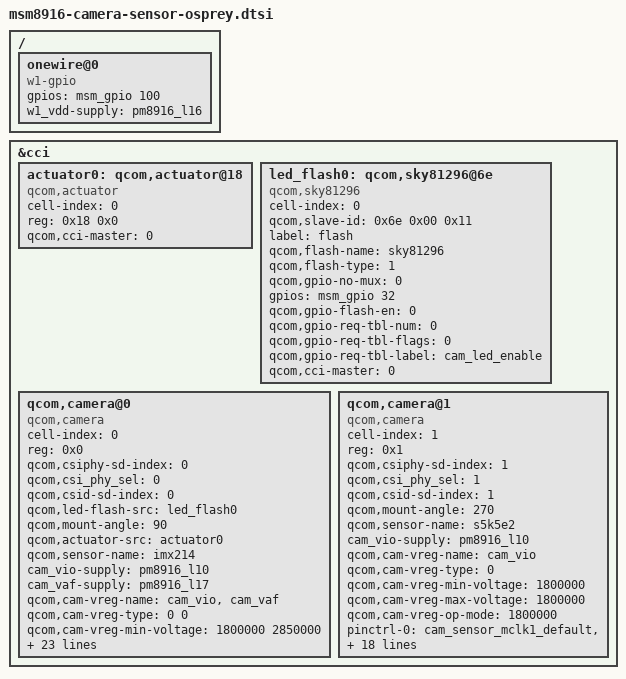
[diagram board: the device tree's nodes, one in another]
/*
 * Copyright (c) 2014, The Linux Foundation. All rights reserved.
 *
 * This program is free software; you can redistribute it and/or modify
 * it under the terms of the GNU General Public License version 2 and
 * only version 2 as published by the Free Software Foundation.
 *
 * This program is distributed in the hope that it will be useful,
 * but WITHOUT ANY WARRANTY; without even the implied warranty of
 * MERCHANTABILITY or FITNESS FOR A PARTICULAR PURPOSE.  See the
 * GNU General Public License for more details.
 */

/ {
	onewire@0 {
		compatible = "w1-gpio";
		gpios = <&msm_gpio 100 0>;
		w1_vdd-supply = <&pm8916_l16>;
	};
};

&cci {
	actuator0: qcom,actuator@18 {
		cell-index = <0>;
		reg = <0x18 0x0>;
		compatible = "qcom,actuator";
		qcom,cci-master = <0>;
	};

	/* skyworks sky81296 flash LED driver*/
	led_flash0: qcom,sky81296@6e {
		cell-index = <0>;
		qcom,slave-id = <0x6e 0x00 0x11>;
		compatible = "qcom,sky81296";
		label = "flash";
		qcom,flash-name = "sky81296";
		qcom,flash-type = <1>;
		qcom,gpio-no-mux = <0>;
		gpios = <&msm_gpio 32 0>;
		qcom,gpio-flash-en = <0>;
		qcom,gpio-req-tbl-num = <0>;
		qcom,gpio-req-tbl-flags = <0>;
		qcom,gpio-req-tbl-label = "cam_led_enable";
		qcom,cci-master = <0>;
	};

	qcom,camera@0 {
		cell-index = <0>;
		compatible = "qcom,camera";
		reg = <0x0>;
		qcom,csiphy-sd-index = <0>;
		qcom,csi_phy_sel = <0>;
		qcom,csid-sd-index = <0>;
		qcom,led-flash-src = <&led_flash0>;
		qcom,mount-angle = <90>;
		qcom,actuator-src = <&actuator0>;
		qcom,sensor-name = "imx214";
		cam_vio-supply = <&pm8916_l10>;
		cam_vaf-supply = <&pm8916_l17>;
		qcom,cam-vreg-name = "cam_vio", "cam_vaf";
		qcom,cam-vreg-type = <0 0>;
		qcom,cam-vreg-min-voltage = <1800000 2850000>;
		qcom,cam-vreg-max-voltage = <1800000 2850000>;
		qcom,cam-vreg-op-mode = <1800000 2850000>;
		pinctrl-names = "cam_default", "cam_suspend";
		pinctrl-0 = <&cam_sensor_mclk0_default
			&cam_sensor_rear_default>;
		pinctrl-1 = <&cam_sensor_mclk0_sleep &cam_sensor_rear_sleep>;
		gpios = <&msm_gpio 26 0>,
			<&msm_gpio 33 0>,
			<&msm_gpio 81 0>,
			<&msm_gpio 35 0>;
		qcom,gpio-vana = <1>;
		qcom,gpio-vdig = <2>;
		qcom,gpio-reset = <3>;
		qcom,gpio-req-tbl-num = <0 1 2 3>;
		qcom,gpio-req-tbl-flags = <0 0 0 0 0>;
		qcom,gpio-req-tbl-label = "CAMIF_MCLK",
                                        "CAM_VANA",
                                        "CAM_VDIG",
                                        "CAM_RESET";
		qcom,csi-lane-assign = <0x4320>;
		qcom,csi-lane-mask = <0x7>;
		qcom,sensor-position = <0>;
		qcom,sensor-mode = <0>;
		qcom,cci-master = <0>;
		qcom,mclk-23880000;
		clocks = <&clock_gcc clk_mclk0_clk_src>,
			<&clock_gcc clk_gcc_camss_mclk0_clk>;
		clock-names = "cam_src_clk", "cam_clk";
		status = "ok";
	};

	qcom,camera@1 {
		cell-index = <1>;
		compatible = "qcom,camera";
		reg = <0x1>;
		qcom,csiphy-sd-index = <1>;
		qcom,csi_phy_sel = <1>;
		qcom,csid-sd-index = <1>;
		qcom,mount-angle = <270>;
		qcom,sensor-name = "s5k5e2";
		cam_vio-supply = <&pm8916_l10>;
		qcom,cam-vreg-name = "cam_vio";
		qcom,cam-vreg-type = <0>;
		qcom,cam-vreg-min-voltage = <1800000>;
		qcom,cam-vreg-max-voltage = <1800000>;
		qcom,cam-vreg-op-mode = <1800000>;
		pinctrl-names = "cam_default", "cam_suspend";
		pinctrl-0 = <&cam_sensor_mclk1_default
			&cam_sensor_front_default>;
		pinctrl-1 = <&cam_sensor_mclk1_sleep &cam_sensor_front_sleep>;
		gpios = <&msm_gpio 27 0>,
			<&msm_gpio 79 0>,
			<&msm_gpio 28 0>;
		qcom,gpio-vdig = <1>;
		qcom,gpio-reset = <2>;
		qcom,gpio-req-tbl-num = <0 1 2>;
		qcom,gpio-req-tbl-flags = <0 0 0>;
		qcom,gpio-req-tbl-label = "CAMIF_MCLK",
					"CAM_VDIG",
					"CAM_RESET";
		qcom,csi-lane-assign = <0x4320>;
		qcom,csi-lane-mask = <0x7>;
		qcom,sensor-position = <1>;
		qcom,sensor-mode = <1>;
		qcom,cci-master = <0>;
		qcom,mclk-23880000;
		clocks = <&clock_gcc clk_mclk1_clk_src>,
			<&clock_gcc clk_gcc_camss_mclk1_clk>;
		clock-names = "cam_src_clk", "cam_clk";

		status = "ok";
	};
};
